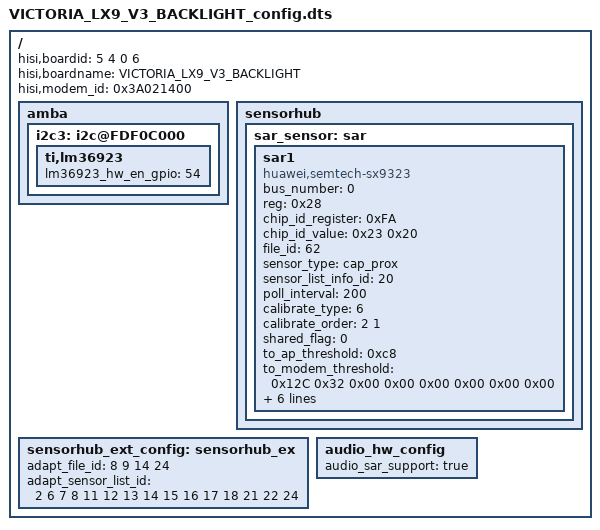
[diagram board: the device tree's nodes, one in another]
/**
 * Huawei Ltd.
 * PhosphorV660
 */

/dts-v1/;

/include/ "fastboot.dtsi"
/include/ "VICTORIA_LX9_V3_config.dtsi"
/include/ "VICTORIA_LX9_V3_BACKLIGHT_pin.dtsi"
/include/ "VICTORIA_LX9_V3_BACKLIGHT_modem_pin.dtsi"
/include/ "VICTORIA_LX9_V3_BACKLIGHT_hi6402_pin.dtsi"

/{
    hisi,boardid = <5 4 0 6>;
    hisi,boardname = "VICTORIA_LX9_V3_BACKLIGHT";
    hisi,modem_id = <0x3A021400>;
    amba {
	i2c3: i2c@FDF0C000 {
		ti,lm36923{
			lm36923_hw_en_gpio = <54>;
		};
	};
    };
	sensorhub{
		sar_sensor:sar{
			sar1{
				compatible="huawei,semtech-sx9323";
				bus_number=<0>;
				reg=<0x28>;
				chip_id_register=<0xFA>;
				chip_id_value=<0x23 0x20>;
				file_id=<62>;
				sensor_type="cap_prox";
				sensor_list_info_id=<20>;
				poll_interval=<200>;
				calibrate_type=<6>;		// bit config 101(b) adapt to the param calibrate calibrate order
				calibrate_order = "2 1";	// 0:free  1:near  2:far  3:other
				shared_flag=<0>;
				status = "ok";
				to_ap_threshold = /bits/ 16 <0xc8>;
				to_modem_threshold = /bits/ 16 <0x12C 0x32 0x00 0x00 0x00 0x00 0x00 0x00>;
				init_reg_val = <0x00000009 0x23012447 0x2C122D0B 0x300B340B 0x3500361F 0x1016>;
				ph = <0x22>;
				calibrate_thred = /bits/ 16 <11000 14550>;//for the factory far calibrate
				sensorlist_name="CAP_PROX sensor-sx9323";
				vendor="semtech";
			};
		};
	};
	sensorhub_ext_config:sensorhub_ex{
		adapt_file_id = <8 9 14 24>;
		adapt_sensor_list_id = <2 6 7 8 11 12 13 14 15 16 17 18 21 22 24>;
	};

	audio_hw_config {
		audio_sar_support = "true";
	};
};
